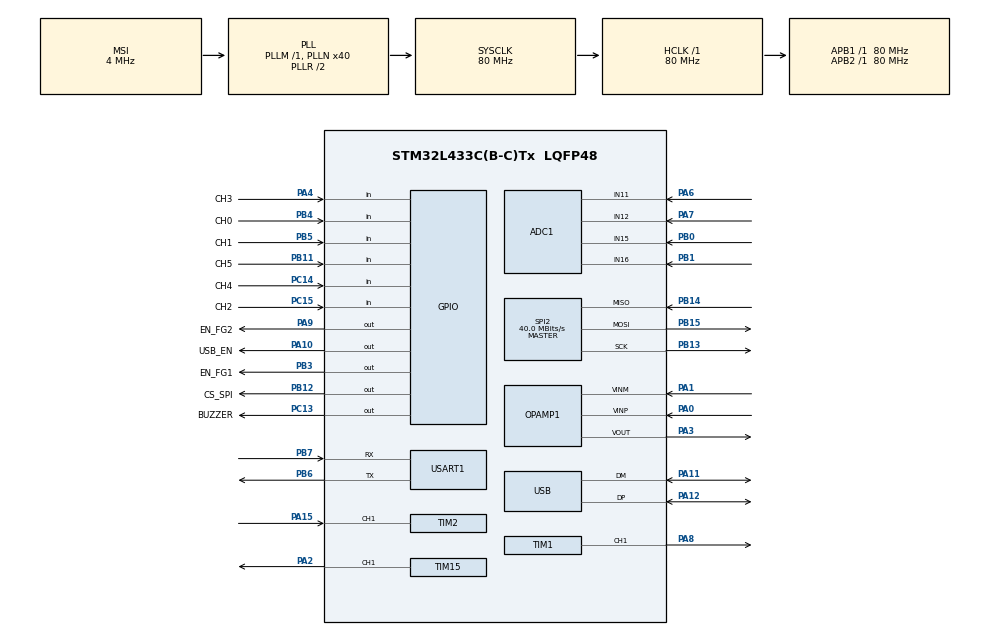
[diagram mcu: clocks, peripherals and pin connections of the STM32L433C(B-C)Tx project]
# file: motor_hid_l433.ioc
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FATFS._USE_LFN=0
SPI2.VirtualType=VM_MASTER
FREERTOS.configUSE_DAEMON_TASK_STARTUP_HOOK=0
FREERTOS.Events01=rtos_event,Dynamic,NULL
VP_USB_DEVICE_VS_USB_DEVICE_CUSTOM_HID_FS.Mode=CUSTOM_HID_FS
VP_RTC_VS_RTC_Activate.Mode=RTC_Enabled
PA15\ (JTDI).Signal=S_TIM2_CH1
PB13.Signal=SPI2_SCK
FATFS._FS_TINY=0
RCC.SYSCLKSource=RCC_SYSCLKSOURCE_PLLCLK
SH.ADCx_IN16.0=ADC1_IN16,IN15-Differential
PA14\ (JTCK-SWCLK).Signal=SYS_JTCK-SWCLK
FREERTOS.INCLUDE_pcTaskGetTaskName=0
USB_DEVICE.USBD_MAX_NUM_INTERFACES=1
RCC.APB2TimFreq_Value=80000000
PB6.Signal=USART1_TX
PB6.Mode=Asynchronous
FREERTOS.configMINIMAL_STACK_SIZE=128
FATFS._LFN_UNICODE=0
RCC.PREFETCH_ENABLE=1
SH.ADCx_IN15.0=ADC1_IN15,IN15-Differential
FATFS._USE_STRFUNC=2
TIM15.Period=65535
PB12.GPIO_Label=CS_SPI
TIM15.TIM_MasterSlaveMode=TIM_MASTERSLAVEMODE_DISABLE
FREERTOS.INCLUDE_xQueueGetMutexHolder=1
TIM1.Channel-PWM\ Generation1\ CH1=TIM_CHANNEL_1
PB14.Mode=Full_Duplex_Master
FREERTOS.HEAP_NUMBER=4
NVIC.TIM2_IRQn=true\:5\:0\:false\:false\:true\:true\:true\:true
PA0.Mode=PGA Connected
SPI2.CalculateBaudRate=40.0 MBits/s
FATFS._USE_MKFS=1
PA8.Signal=S_TIM1_CH1
ADC1.SamplingTime-0\#ChannelRegularConversion=ADC_SAMPLETIME_2CYCLES_5
VP_TIM1_VS_ClockSourceINT.Mode=Internal
FATFS._FS_TIMEOUT=1000
PA0.Signal=OPAMP1_VINP
Mcu.Package=LQFP48
PB9.Signal=I2C1_SDA
TIM2.Prescaler=0
PB1.Signal=ADCx_IN16
FREERTOS.configUSE_NEWLIB_REENTRANT=0
NVIC.TimeBase=TIM1_UP_TIM16_IRQn
SPI2.Mode=SPI_MODE_MASTER
FREERTOS.INCLUDE_vTaskSuspend=1
TIM2.ICPolarity_1=TIM_INPUTCHANNELPOLARITY_FALLING
NVIC.TimeBaseIP=TIM16
PA10.Signal=GPIO_Output
FREERTOS.copyHeapFile=1
FREERTOS.INCLUDE_vTaskPrioritySet=1
FATFS._FS_MINIMIZE=0
RCC.APB1TimFreq_Value=80000000
FREERTOS.configGENERATE_RUN_TIME_STATS=0
TIM1.Period=0xffff
PB13.Mode=Full_Duplex_Master
PA13\ (JTMS-SWDIO).Signal=SYS_JTMS-SWDIO
NVIC.USART1_IRQn=true\:5\:0\:false\:false\:true\:true\:true\:true
PA4.GPIO_Label=CH3
FATFS._MIN_SS=512
RCC.HSI48_VALUE=48000000
TIM15.Channel-PWM\ Generation1\ CH1=TIM_CHANNEL_1
USB_DEVICE.USBD_DEBUG_LEVEL=0
FREERTOS.INCLUDE_xTimerPendFunctionCall=1
FREERTOS.configTIMER_QUEUE_LENGTH=10
FREERTOS.configIDLE_SHOULD_YIELD=1
PC15-OSC32_OUT\ (PC15).GPIO_Label=CH2
FREERTOS.Tasks01=console,24,512,process_console,Default,NULL,Dynamic,NULL,NULL;button,48,128,process_button,Default,NULL,Dynamic,NULL,NULL;buzzer,8,128,process_buzzer,Default,NULL,Dynamic,NULL,NULL;timer0,24,128,process_timer0,Default,NULL,Dynamic,NULL,NULL
ADC1.Rank-0\#ChannelRegularConversion=1
FREERTOS.INCLUDE_xTaskGetCurrentTaskHandle=1
FREERTOS.configLIBRARY_LOWEST_INTERRUPT_PRIORITY=15
ADC1.OffsetNumber-0\#ChannelRegularConversion=ADC_OFFSET_NONE
PC13.Signal=GPIO_Output
PA9.GPIO_Label=EN_FG2
FREERTOS.INCLUDE_vTaskDelayUntil=1
FREERTOS.configCHECK_FOR_STACK_OVERFLOW=0
PB11.GPIO_Label=CH5
PC14-OSC32_IN\ (PC14).GPIO_Label=CH4
FATFS._VOLUMES=1
PA3.Mode=PGA Connected
TIM1.AutoReloadPreload=TIM_AUTORELOAD_PRELOAD_ENABLE
ADC1.SingleDiff-0\#ChannelRegularConversion=ADC_DIFFERENTIAL_ENDED
USB_DEVICE.VID=1155
Dma.USART1_RX.0.Direction=DMA_PERIPH_TO_MEMORY
PA9.Signal=GPIO_Output
Dma.USART1_RX.0.PeriphInc=DMA_PINC_DISABLE
PB14.Signal=SPI2_MISO
NVIC.TIM1_BRK_TIM15_IRQn=true\:5\:0\:false\:false\:true\:true\:true\:true
SH.S_TIM15_CH1.0=TIM15_CH1,PWM Generation1 CH1
PA1.Mode=PGA Connected
FREERTOS.configUSE_CO_ROUTINES=0
FREERTOS.configUSE_MUTEXES=1
FREERTOS.INCLUDE_xEventGroupSetBitFromISR=0
TIM2.Period=0xffffffff
FREERTOS.configMAX_CO_ROUTINE_PRIORITIES=2
FATFS._USE_FIND=0
FREERTOS.INCLUDE_xTaskResumeFromISR=1
PA13\ (JTMS-SWDIO).Mode=Serial_Wire
PA4.Signal=GPIO_Input
FREERTOS.configLIBRARY_MAX_SYSCALL_INTERRUPT_PRIORITY=5
PB5.Signal=GPIO_Input
ADC1.master=1
FREERTOS.configUSE_COUNTING_SEMAPHORES=1
PB5.GPIO_PuPd=GPIO_PULLUP
PA11.Signal=USB_DM
ProjectManager.HeapSize=0x800
FREERTOS.configUSE_RECURSIVE_MUTEXES=1
FREERTOS.Mutexes01=cdc_tx_mutex,Dynamic,NULL;uart_tx_mutex,Dynamic,NULL;cdc_rx_mutex,Dynamic,NULL;pwm_set_mutex,Dynamic,NULL
NVIC.PriorityGroup=NVIC_PRIORITYGROUP_4
USB.phy_itface=PCD_PHY_EMBEDDED
TIM2.TIM_MasterSlaveMode=TIM_MASTERSLAVEMODE_DISABLE
TIM2.AutoReloadPreload=TIM_AUTORELOAD_PRELOAD_ENABLE
PB4\ (NJTRST).GPIO_Label=CH0
TIM15.Pulse-PWM\ Generation1\ CH1=0x0
TIM15.TIM_MasterOutputTrigger=TIM_TRGO_RESET
PB0.Signal=ADCx_IN15
PB4\ (NJTRST).GPIO_PuPd=GPIO_PULLUP
Mcu.Family=STM32L4
FATFS._USE_FORWARD=0
USB_DEVICE.CLASS_NAME_FS=CUSTOM_HID
TIM15.AutoReloadPreload=TIM_AUTORELOAD_PRELOAD_ENABLE
RCC.CortexFreq_Value=80000000
PC14-OSC32_IN\ (PC14).GPIO_PuPd=GPIO_PULLUP
FREERTOS.INCLUDE_xTaskGetSchedulerState=1
NVIC.USB_IRQn=true\:5\:0\:false\:false\:true\:true\:false\:true
TIM15.ClockDivision=TIM_CLOCKDIVISION_DIV1
PA11.Mode=Device
FREERTOS.configTICK_RATE_HZ=1000
VP_SYS_VS_tim16.Mode=TIM16
TIM1.Pulse-PWM\ Generation1\ CH1=0x0
PB11.GPIO_PuPd=GPIO_PULLUP
PC13.GPIO_Label=BUZZER
PB11.Signal=GPIO_Input
PB15.Signal=SPI2_MOSI
FREERTOS.configUSE_TASK_NOTIFICATIONS=1
ProjectManager.StackSize=0x400
PB3\ (JTDO-TRACESWO).Signal=GPIO_Output
VP_FREERTOS_VS_CMSIS_V2.Mode=CMSIS_V2
USB_DEVICE.MANUFACTURER_STRING=STMicroelectronics
PA12.Signal=USB_DP
FATFS._MAX_LFN=255
TIM15.Prescaler=0
FREERTOS.configUSE_STATS_FORMATTING_FUNCTIONS=0
RCC.HCLKFreq_Value=80000000
RCC.FLatency=FLASH_LATENCY_4
FATFS._MULTI_PARTITION=0
TIM2.ClockDivision=TIM_CLOCKDIVISION_DIV1
FREERTOS.configUSE_MALLOC_FAILED_HOOK=0
FREERTOS.configQUEUE_REGISTRY_SIZE=8
RCC.AHBFreq_Value=80000000
SPI2.BaudRatePrescaler=SPI_BAUDRATEPRESCALER_2
Dma.USART1_RX.0.Priority=DMA_PRIORITY_LOW
FREERTOS.configUSE_PREEMPTION=1
ADC1.Channel-0\#ChannelRegularConversion=ADC_CHANNEL_15
RCC.HSE_VALUE=8000000
PA4.GPIO_PuPd=GPIO_PULLUP
FREERTOS.configENABLE_BACKWARD_COMPATIBILITY=1
USB_DEVICE.USBD_SELF_POWERED=1
PA10.GPIO_Label=USB_EN
PB7.Signal=USART1_RX
FREERTOS.INCLUDE_vTaskCleanUpResources=0
Dma.USART1_RX.0.MemInc=DMA_MINC_ENABLE
FREERTOS.configTIMER_TASK_PRIORITY=2
FREERTOS.configTOTAL_HEAP_SIZE=5120
FATFS._USE_LABEL=0
USB.battery_charging_enable=DISABLE
PA6.Signal=ADCx_IN11
FREERTOS.INCLUDE_xTaskAbortDelay=0
USB.DeviceSpeed=PCD_SPEED_FULL
TIM2.TIM_MasterOutputTrigger=TIM_TRGO_RESET
FATFS._FS_LOCK=2
PB5.GPIO_Label=CH1
FREERTOS.configUSE_TICK_HOOK=0
Dma.USART1_RX.0.Mode=DMA_NORMAL
FATFS._FS_RPATH=0
SPI2.Direction=SPI_DIRECTION_2LINES
FREERTOS.configMAX_TASK_NAME_LEN=16
Dma.Request0=USART1_RX
Dma.USART1_RX.0.Instance=DMA2_Channel7
RCC.PLLSAI1N=24
PA3.Signal=OPAMP1_VOUT
RCC.MSI_VALUE=4000000
PA14\ (JTCK-SWCLK).Mode=Serial_Wire
SH.S_TIM2_CH1.0=TIM2_CH1,PWM_Input_1
FATFS._FS_REENTRANT=1
Dma.USART1_RX.0.PeriphDataAlignment=DMA_PDATAALIGN_BYTE
TIM2.CounterMode=TIM_COUNTERMODE_UP
USB_DEVICE.VirtualModeFS=Custom_Hid_FS
FATFS._FS_NOFSINFO=0
RCC.I2C1CLockSelection=RCC_I2C1CLKSOURCE_HSI
FREERTOS.configUSE_TICKLESS_IDLE=0
PC15-OSC32_OUT\ (PC15).Signal=GPIO_Input
FREERTOS.INCLUDE_vTaskDelay=1
PB3\ (JTDO-TRACESWO).GPIO_Label=EN_FG1
FREERTOS.configUSE_APPLICATION_TASK_TAG=0
FREERTOS.INCLUDE_uxTaskGetStackHighWaterMark=1
USART1.VirtualMode-Asynchronous=VM_ASYNC
FREERTOS.configUSE_IDLE_HOOK=0
FREERTOS.INCLUDE_vTaskDelete=1
SH.ADCx_IN12.0=ADC1_IN12,IN11-Differential
SH.S_TIM1_CH1.0=TIM1_CH1,PWM Generation1 CH1
FREERTOS.configRECORD_STACK_HIGH_ADDRESS=0
ProjectManager.TargetToolchain=STM32CubeIDE
FREERTOS.configUSE_TRACE_FACILITY=1
FREERTOS.configTIMER_TASK_STACK_DEPTH=256
FATFS._CODE_PAGE=850
RCC.USBFreq_Value=48000000
RCC.LSE_VALUE=32768
PA1.Signal=OPAMP1_VINM
VP_FATFS_VS_Generic.Mode=User_defined
USB_DEVICE.LANGID_STRING=1033
FATFS._STRF_ENCODE=3
board=custom
RCC.VCOOutputFreq_Value=160000000
FATFS._USE_FASTSEEK=1
USB.low_power_enable=DISABLE
PB15.Mode=Full_Duplex_Master
PC15-OSC32_OUT\ (PC15).GPIO_PuPd=GPIO_PULLUP
FATFS._FS_NORTC=0
FREERTOS.INCLUDE_eTaskGetState=1
RCC.APB2Freq_Value=80000000
SH.ADCx_IN11.0=ADC1_IN11,IN11-Differential
VP_TIM2_VS_ClockSourceINT.Mode=Internal
RCC.ADCFreq_Value=48000000
Dma.USART1_RX.0.MemDataAlignment=DMA_MDATAALIGN_BYTE
FREERTOS.INCLUDE_uxTaskPriorityGet=1
Mcu.Name=STM32L433C(B-C)Tx
FREERTOS.INCLUDE_xSemaphoreGetMutexHolder=0
PA2.Signal=S_TIM15_CH1
FATFS._MAX_SS=512
RCC.SYSCLKFreq_VALUE=80000000
PA12.Mode=Device
PC14-OSC32_IN\ (PC14).Signal=GPIO_Input
PB7.Mode=Asynchronous
VP_TIM15_VS_ClockSourceINT.Mode=Internal
FREERTOS.INCLUDE_xTaskGetHandle=0
NVIC.DMA2_Channel7_IRQn=true\:5\:0\:false\:false\:true\:true\:false\:true
USB_DEVICE.USBD_MAX_NUM_CONFIGURATION=1
FATFS._USE_TRIM=0
RCC.HSI_VALUE=16000000
NVIC.TIM1_UP_TIM16_IRQn=true\:0\:0\:false\:false\:true\:false\:true\:true
ADC1.NbrOfConversionFlag=1
RCC.PLLN=40
PB8.Signal=I2C1_SCL
FATFS._FS_READONLY=0
TIM15.CounterMode=TIM_COUNTERMODE_UP
RCC.APB1Freq_Value=80000000
USB_DEVICE.VirtualMode=CustomHid
USB_DEVICE.USBD_MAX_STR_DESC_SIZ=512
PB12.Signal=GPIO_Output
PA7.Signal=ADCx_IN12
PB4\ (NJTRST).Signal=GPIO_Input

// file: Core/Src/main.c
/* USER CODE BEGIN Header */
/**
  ******************************************************************************
  * @file           : main.c
  * @brief          : Main program body
  ******************************************************************************
  * @attention
  *
  * <h2><center>&copy; Copyright (c) 2021 STMicroelectronics.
  * All rights reserved.</center></h2>
  *
  * This software component is licensed by ST under Ultimate Liberty license
  * SLA0044, the "License"; You may not use this file except in compliance with
  * the License. You may obtain a copy of the License at:
  *                             www.st.com/SLA0044
  *
  ******************************************************************************
  */
/* USER CODE END Header */
#include "main.h"
#include "cmsis_os.h"
#include "adc.h"
#include "dma.h"
#include "fatfs.h"
#include "opamp.h"
#include "rtc.h"
#include "spi.h"
#include "tim.h"
#include "usart.h"
#include "usb_device.h"
#include "gpio.h"

void SystemClock_Config(void);
void MX_FREERTOS_Init(void);

int main(void)
{

  /* MCU Configuration--------------------------------------------------------*/

  /* Reset of all peripherals, Initializes the Flash interface and the Systick. */
  HAL_Init();

  /* Configure the system clock */
  SystemClock_Config();

  /* Initialize all configured peripherals */
  MX_GPIO_Init();
  MX_DMA_Init();
  MX_SPI2_Init();
  MX_TIM2_Init();
  MX_FATFS_Init();
  MX_TIM15_Init();
  MX_USART1_UART_Init();
  MX_TIM1_Init();
  MX_RTC_Init();
  MX_ADC1_Init();
  MX_OPAMP1_Init();

  /* Init scheduler */
  osKernelInitialize();  /* Call init function for freertos objects (in freertos.c) */
  MX_FREERTOS_Init();
  /* Start scheduler */
  osKernelStart();

  /* We should never get here as control is now taken by the scheduler */
  /* Infinite loop */
  while (1)
  {

  }
}

void SystemClock_Config(void)
{
  RCC_OscInitTypeDef RCC_OscInitStruct = {0};
  RCC_ClkInitTypeDef RCC_ClkInitStruct = {0};
  RCC_PeriphCLKInitTypeDef PeriphClkInit = {0};

  /** Initializes the RCC Oscillators according to the specified parameters
  * in the RCC_OscInitTypeDef structure.
  */
  RCC_OscInitStruct.OscillatorType = RCC_OSCILLATORTYPE_LSI|RCC_OSCILLATORTYPE_MSI;
  RCC_OscInitStruct.LSIState = RCC_LSI_ON;
  RCC_OscInitStruct.MSIState = RCC_MSI_ON;
  RCC_OscInitStruct.MSICalibrationValue = 0;
  RCC_OscInitStruct.MSIClockRange = RCC_MSIRANGE_6;
  RCC_OscInitStruct.PLL.PLLState = RCC_PLL_ON;
  RCC_OscInitStruct.PLL.PLLSource = RCC_PLLSOURCE_MSI;
  RCC_OscInitStruct.PLL.PLLM = 1;
  RCC_OscInitStruct.PLL.PLLN = 40;
  RCC_OscInitStruct.PLL.PLLP = RCC_PLLP_DIV7;
  RCC_OscInitStruct.PLL.PLLQ = RCC_PLLQ_DIV2;
  RCC_OscInitStruct.PLL.PLLR = RCC_PLLR_DIV2;
  if (HAL_RCC_OscConfig(&RCC_OscInitStruct) != HAL_OK)
  {
    Error_Handler();
  }
  /** Initializes the CPU, AHB and APB buses clocks
  */
  RCC_ClkInitStruct.ClockType = RCC_CLOCKTYPE_HCLK|RCC_CLOCKTYPE_SYSCLK
                              |RCC_CLOCKTYPE_PCLK1|RCC_CLOCKTYPE_PCLK2;
  RCC_ClkInitStruct.SYSCLKSource = RCC_SYSCLKSOURCE_PLLCLK;
  RCC_ClkInitStruct.AHBCLKDivider = RCC_SYSCLK_DIV1;
  RCC_ClkInitStruct.APB1CLKDivider = RCC_HCLK_DIV1;
  RCC_ClkInitStruct.APB2CLKDivider = RCC_HCLK_DIV1;

  if (HAL_RCC_ClockConfig(&RCC_ClkInitStruct, FLASH_LATENCY_4) != HAL_OK)
  {
    Error_Handler();
  }
  PeriphClkInit.PeriphClockSelection = RCC_PERIPHCLK_RTC|RCC_PERIPHCLK_USART1
                              |RCC_PERIPHCLK_USB|RCC_PERIPHCLK_ADC;
  PeriphClkInit.Usart1ClockSelection = RCC_USART1CLKSOURCE_PCLK2;
  PeriphClkInit.AdcClockSelection = RCC_ADCCLKSOURCE_PLLSAI1;
  PeriphClkInit.RTCClockSelection = RCC_RTCCLKSOURCE_LSI;
  PeriphClkInit.UsbClockSelection = RCC_USBCLKSOURCE_PLLSAI1;
  PeriphClkInit.PLLSAI1.PLLSAI1Source = RCC_PLLSOURCE_MSI;
  PeriphClkInit.PLLSAI1.PLLSAI1M = 1;
  PeriphClkInit.PLLSAI1.PLLSAI1N = 24;
  PeriphClkInit.PLLSAI1.PLLSAI1P = RCC_PLLP_DIV7;
  PeriphClkInit.PLLSAI1.PLLSAI1Q = RCC_PLLQ_DIV2;
  PeriphClkInit.PLLSAI1.PLLSAI1R = RCC_PLLR_DIV2;
  PeriphClkInit.PLLSAI1.PLLSAI1ClockOut = RCC_PLLSAI1_48M2CLK|RCC_PLLSAI1_ADC1CLK;
  if (HAL_RCCEx_PeriphCLKConfig(&PeriphClkInit) != HAL_OK)
  {
    Error_Handler();
  }
  /** Configure the main internal regulator output voltage
  */
  if (HAL_PWREx_ControlVoltageScaling(PWR_REGULATOR_VOLTAGE_SCALE1) != HAL_OK)
  {
    Error_Handler();
  }
}

 /**
  * @brief  Period elapsed callback in non blocking mode
  * @note   This function is called  when TIM16 interrupt took place, inside
  * HAL_TIM_IRQHandler(). It makes a direct call to HAL_IncTick() to increment
  * a global variable "uwTick" used as application time base.
  * @param  htim : TIM handle
  * @retval None
  */
void HAL_TIM_PeriodElapsedCallback(TIM_HandleTypeDef *htim)
{
  if (htim->Instance == TIM16) {
    HAL_IncTick();
  }
}

void Error_Handler(void)
{
  __disable_irq();
  while (1)
  {
  }
}

/************************ (C) COPYRIGHT STMicroelectronics *****END OF FILE****/

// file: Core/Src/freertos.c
/* USER CODE BEGIN Header */
/**
 ******************************************************************************
 * File Name          : freertos.c
 * Description        : Code for freertos applications
 ******************************************************************************
 * @attention
 *
 * <h2><center>&copy; Copyright (c) 2021 STMicroelectronics.
 * All rights reserved.</center></h2>
 *
 * This software component is licensed by ST under Ultimate Liberty license
 * SLA0044, the "License"; You may not use this file except in compliance with
 * the License. You may obtain a copy of the License at:
 *                             www.st.com/SLA0044
 *
 ******************************************************************************
 */
/* USER CODE END Header */

#include "FreeRTOS.h"
#include "task.h"
#include "main.h"
#include "cmsis_os.h"

/* USER CODE BEGIN Includes */
//#include <stdio.h>
#include <string.h>
#include "my_hid.h"
/* USER CODE END Includes */

/* Definitions for console */
osThreadId_t consoleHandle;
const osThreadAttr_t console_attributes =
{ .name = "console", .stack_size = 512 * 4, .priority =
		(osPriority_t) osPriorityNormal, };
/* Definitions for button */
osThreadId_t buttonHandle;
const osThreadAttr_t button_attributes =
{ .name = "button", .stack_size = 128 * 4, .priority =
		(osPriority_t) osPriorityRealtime, };
/* Definitions for buzzer */
osThreadId_t buzzerHandle;
const osThreadAttr_t buzzer_attributes =
{ .name = "buzzer", .stack_size = 128 * 4, .priority =
		(osPriority_t) osPriorityLow, };
/* Definitions for timer0 */
osThreadId_t timer0Handle;
const osThreadAttr_t timer0_attributes =
{ .name = "timer0", .stack_size = 128 * 4, .priority =
		(osPriority_t) osPriorityNormal, };
/* Definitions for cdc_tx_mutex */
osMutexId_t cdc_tx_mutexHandle;
const osMutexAttr_t cdc_tx_mutex_attributes =
{ .name = "cdc_tx_mutex" };
/* Definitions for uart_tx_mutex */
osMutexId_t uart_tx_mutexHandle;
const osMutexAttr_t uart_tx_mutex_attributes =
{ .name = "uart_tx_mutex" };
/* Definitions for cdc_rx_mutex */
osMutexId_t cdc_rx_mutexHandle;
const osMutexAttr_t cdc_rx_mutex_attributes =
{ .name = "cdc_rx_mutex" };
/* Definitions for pwm_set_mutex */
osMutexId_t pwm_set_mutexHandle;
const osMutexAttr_t pwm_set_mutex_attributes =
{ .name = "pwm_set_mutex" };
/* Definitions for rtos_event */
osEventFlagsId_t rtos_eventHandle;
const osEventFlagsAttr_t rtos_event_attributes =
{ .name = "rtos_event" };

void process_console(void *argument);
void process_button(void *argument);
void process_buzzer(void *argument);
void process_timer0(void *argument);

extern void MX_USB_DEVICE_Init(void);
void MX_FREERTOS_Init(void); /* (MISRA C 2004 rule 8.1) */

void MX_FREERTOS_Init(void)
{
	/* Create the mutex(es) */
	/* creation of cdc_tx_mutex */
	cdc_tx_mutexHandle = osMutexNew(&cdc_tx_mutex_attributes);

	/* creation of uart_tx_mutex */
	uart_tx_mutexHandle = osMutexNew(&uart_tx_mutex_attributes);

	/* creation of cdc_rx_mutex */
	cdc_rx_mutexHandle = osMutexNew(&cdc_rx_mutex_attributes);

	/* creation of pwm_set_mutex */
	pwm_set_mutexHandle = osMutexNew(&pwm_set_mutex_attributes);

	/* Create the thread(s) */
	/* creation of console */
	consoleHandle = osThreadNew(process_console, NULL, &console_attributes);

	/* creation of button */
	buttonHandle = osThreadNew(process_button, NULL, &button_attributes);

	/* creation of buzzer */
	buzzerHandle = osThreadNew(process_buzzer, NULL, &buzzer_attributes);

	/* creation of timer0 */
	timer0Handle = osThreadNew(process_timer0, NULL, &timer0_attributes);

	/* creation of rtos_event */
	rtos_eventHandle = osEventFlagsNew(&rtos_event_attributes);

}

void process_console(void *argument)
{
	/* init code for USB_DEVICE */
	MX_USB_DEVICE_Init();
	/* USER CODE BEGIN process_console */
	/* Infinite loop */
	for (;;)
	{
		if (is_hid_out_empty == false)
		{
			memcpy(hid_in_report, hid_out_report, 64);
			for (int i = 0; i < 64; i++)
			{
				hid_in_report[i] = hid_out_report[i];
			}
			USBD_CUSTOM_HID_SendReport_FS(hid_in_report, 64);
			is_hid_out_empty = true;
		}

		osDelay(1);
	}
	/* USER CODE END process_console */
}

void process_button(void *argument)
{
	for (;;)
	{
		osDelay(1);
	}
}

void process_buzzer(void *argument)
{
	for (;;)
	{
		osDelay(1);
	}
}

void process_timer0(void *argument)
{
	for (;;)
	{
		osDelay(1);
	}
}

/************************ (C) COPYRIGHT STMicroelectronics *****END OF FILE****/
